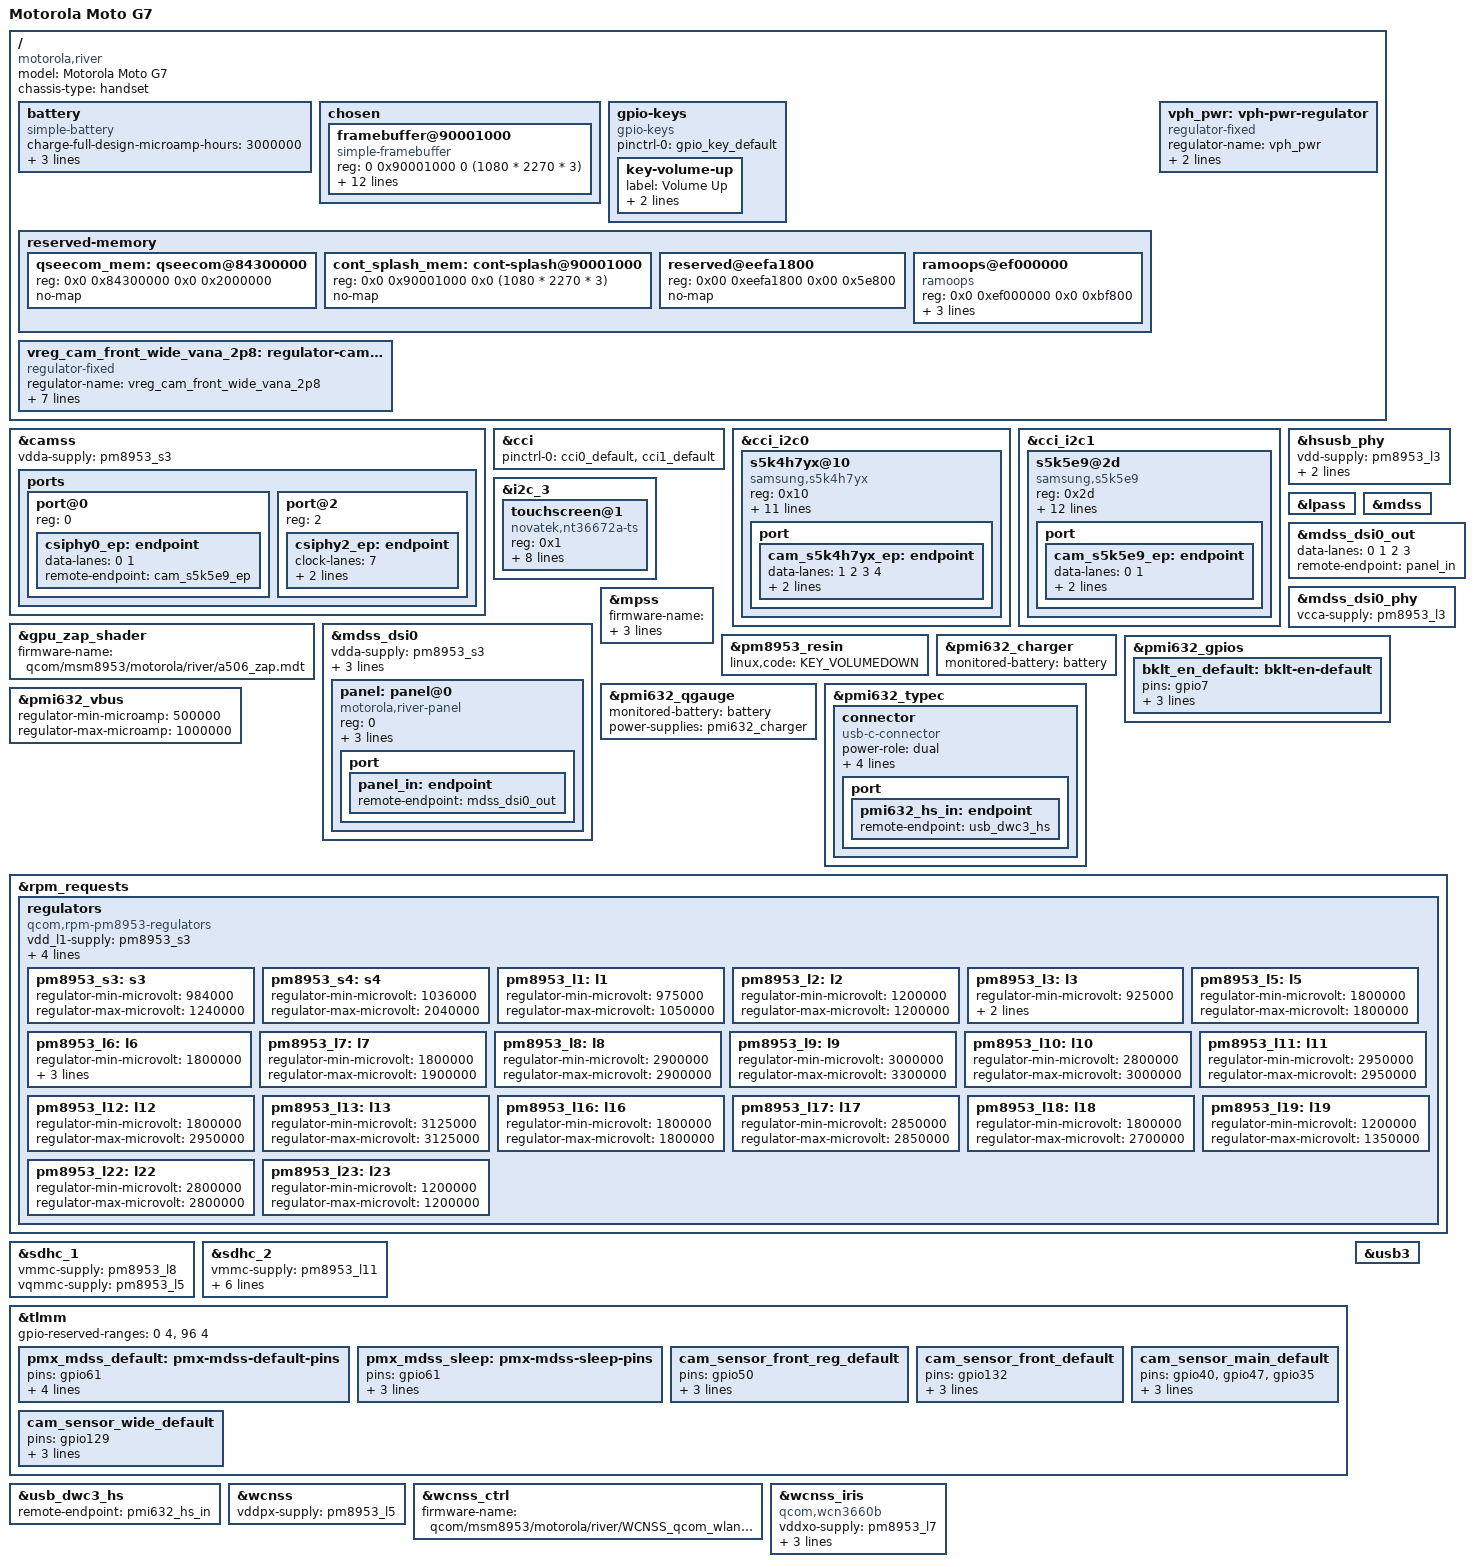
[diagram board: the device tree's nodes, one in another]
// SPDX-License-Identifier: BSD-3-Clause
/*
 * Copyright (c) 2022, Gabriela David
 * Copyright (c) 2026, Val Packett <val@packett.cool>
 */
/dts-v1/;

#include "sdm632.dtsi"
#include "pm8953.dtsi"
#include "pmi632.dtsi"

/delete-node/ &cont_splash_mem;
/delete-node/ &qseecom_mem;

/ {
	model = "Motorola Moto G7";
	compatible = "motorola,river", "qcom,sdm632";
	chassis-type = "handset";

	battery: battery {
		compatible = "simple-battery";

		charge-full-design-microamp-hours = <3000000>;
		/* XXX: Conservative value, downstream qcom,fastchg-current-ma is 3A */
		constant-charge-current-max-microamp = <1500000>;
		voltage-min-design-microvolt = <3400000>;
		voltage-max-design-microvolt = <4400000>;
	};

	chosen {
		#address-cells = <2>;
		#size-cells = <2>;
		ranges;

		framebuffer@90001000 {
			compatible = "simple-framebuffer";
			reg = <0 0x90001000 0 (1080 * 2270 * 3)>;

			width = <1080>;
			height = <2270>;
			stride = <(1080 * 3)>;
			format = "r8g8b8";

			power-domains = <&gcc MDSS_GDSC>;

			clocks = <&gcc GCC_MDSS_AHB_CLK>,
				 <&gcc GCC_MDSS_AXI_CLK>,
				 <&gcc GCC_MDSS_VSYNC_CLK>,
				 <&gcc GCC_MDSS_MDP_CLK>,
				 <&gcc GCC_MDSS_BYTE0_CLK>,
				 <&gcc GCC_MDSS_PCLK0_CLK>,
				 <&gcc GCC_MDSS_ESC0_CLK>;
		};
	};

	gpio-keys {
		compatible = "gpio-keys";

		pinctrl-0 = <&gpio_key_default>;
		pinctrl-names = "default";

		key-volume-up {
			label = "Volume Up";
			gpios = <&tlmm 85 GPIO_ACTIVE_LOW>;
			linux,code = <KEY_VOLUMEUP>;
		};
	};

	reserved-memory {
		qseecom_mem: qseecom@84300000 {
			reg = <0x0 0x84300000 0x0 0x2000000>;
			no-map;
		};

		cont_splash_mem: cont-splash@90001000 {
			reg = <0x0 0x90001000 0x0 (1080 * 2270 * 3)>;
			no-map;
		};

		reserved@eefa1800 {
			reg = <0x00 0xeefa1800 0x00 0x5e800>;
			no-map;
		};

		ramoops@ef000000 {
			compatible = "ramoops";
			reg = <0x0 0xef000000 0x0 0xbf800>;
			console-size = <0x40000>;
			pmsg-size = <0x40000>;
			record-size = <0x3f800>;
		};
	};

	vreg_cam_front_wide_vana_2p8: regulator-cam-front-wide-vana {
		compatible = "regulator-fixed";
		regulator-name = "vreg_cam_front_wide_vana_2p8";

		regulator-min-microvolt = <2800000>;
		regulator-max-microvolt = <2800000>;

		gpio = <&tlmm 50 GPIO_ACTIVE_HIGH>;
		enable-active-high;

		pinctrl-names = "default";
		pinctrl-0 = <&cam_sensor_front_reg_default>;

		vin-supply = <&pm8953_l22>;

		regulator-always-on;
	};

	vph_pwr: vph-pwr-regulator {
		compatible = "regulator-fixed";
		regulator-name = "vph_pwr";
		regulator-always-on;
		regulator-boot-on;
	};
};

&camss {
	status = "okay";
	vdda-supply = <&pm8953_s3>;

	ports {
		port@0 {
			reg = <0>;

			csiphy0_ep: endpoint {
				data-lanes = <0 1>;
				remote-endpoint = <&cam_s5k5e9_ep>;
			};
		};

		port@2 {
			reg = <2>;

			csiphy2_ep: endpoint {
				clock-lanes = <7>;
				data-lanes = <0 1 2 3>;
				remote-endpoint = <&cam_s5k4h7yx_ep>;
			};
		};
	};
};

&cci {
	pinctrl-0 = <&cci0_default &cci1_default>;
	pinctrl-names = "default";

	status = "okay";
};

&cci_i2c0 {
	s5k4h7yx@10 { /* Front camera */
		compatible = "samsung,s5k4h7yx";
		reg = <0x10>;

		vdda-supply = <&vreg_cam_front_wide_vana_2p8>;
		vddd-supply = <&pm8953_l23>;
		vddio-supply = <&pm8953_l6>;

		clocks = <&gcc GCC_CAMSS_MCLK1_CLK>;
		assigned-clocks = <&gcc GCC_CAMSS_MCLK1_CLK>;
		assigned-clock-rates = <24000000>;

		reset-gpios = <&tlmm 132 GPIO_ACTIVE_LOW>; /* "standby" downstream */
		pinctrl-0 = <&camss_mclk1_default &cam_sensor_front_default>;
		pinctrl-names = "default";

		orientation = <0>;
		rotation = <90>;

		port {
			cam_s5k4h7yx_ep: endpoint {
				data-lanes = <1 2 3 4>;
				link-frequencies = /bits/ 64 <600000000>; // FIXME
				remote-endpoint = <&csiphy2_ep>;
			};
		};
	};
};

&cci_i2c1 {
	s5k5e9@2d { /* Wide camera */
		compatible = "samsung,s5k5e9";
		reg = <0x2d>;

		vana-supply = <&vreg_cam_front_wide_vana_2p8>;
		vdig-supply = <&pm8953_l23>;
		vio-supply = <&pm8953_l6>;

		clocks = <&gcc GCC_CAMSS_MCLK2_CLK>;
		clock-names = "xvclk";
		clock-frequency = <19200000>;
		assigned-clocks = <&gcc GCC_CAMSS_MCLK2_CLK>;
		assigned-clock-rates = <19200000>;

		reset-gpios = <&tlmm 129 GPIO_ACTIVE_HIGH>;
		pinctrl-0 = <&camss_mclk2_default &cam_sensor_wide_default>;
		pinctrl-names = "default";

		orientation = <1>;
		rotation = <270>;

		port {
			cam_s5k5e9_ep: endpoint {
				data-lanes = <0 1>;
				link-frequencies = /bits/ 64 <480000000>;
				remote-endpoint = <&csiphy0_ep>;
			};
		};
	};
};

&gpu_zap_shader {
	firmware-name = "qcom/msm8953/motorola/river/a506_zap.mdt";
};

&hsusb_phy {
	vdd-supply = <&pm8953_l3>;
	vdda-pll-supply = <&pm8953_l7>;
	vdda-phy-dpdm-supply = <&pm8953_l13>;

	status = "okay";
};

&i2c_3 {
	status = "okay";

	touchscreen@1 {
		compatible = "novatek,nt36672a-ts";
		reg = <0x1>;

		interrupts-extended = <&tlmm 65 IRQ_TYPE_EDGE_FALLING>;
		reset-gpios = <&tlmm 64 GPIO_ACTIVE_HIGH>;
		panel = <&panel>;

		iovcc-supply = <&pm8953_l6>;
		vcc-supply = <&pm8953_l10>;

		touchscreen-size-x = <1080>;
		touchscreen-size-y = <2270>;
	};
};

&lpass {
	status = "okay";
};

&mdss {
	status = "okay";
};

&mdss_dsi0 {
	vdda-supply = <&pm8953_s3>;
	vddio-supply = <&pm8953_l6>;

	pinctrl-0 = <&pmx_mdss_default &mdss_te_default>;
	pinctrl-1 = <&pmx_mdss_sleep &mdss_te_default>;
	pinctrl-names = "default", "sleep";

	status = "okay";

	panel: panel@0 {
		compatible = "motorola,river-panel";
		reg = <0>;

		reset-gpios = <&tlmm 61 GPIO_ACTIVE_LOW>;

		iovcc-supply = <&pm8953_l6>;

		pinctrl-0 = <&bklt_en_default>;
		pinctrl-names = "default";

		port {
			panel_in: endpoint {
				remote-endpoint = <&mdss_dsi0_out>;
			};
		};
	};
};

&mdss_dsi0_out {
	data-lanes = <0 1 2 3>;
	remote-endpoint = <&panel_in>;
};

&mdss_dsi0_phy {
	vcca-supply = <&pm8953_l3>;

	status = "okay";
};

&mpss {
	firmware-name = "qcom/msm8953/motorola/river/mba.mbn",
			"qcom/msm8953/motorola/river/modem.mbn";
	pll-supply = <&pm8953_l7>;

	status = "okay";
};

&pm8953_resin {
	linux,code = <KEY_VOLUMEDOWN>;
	status = "okay";
};

&pmi632_charger {
	monitored-battery = <&battery>;

	status = "okay";
};

&pmi632_gpios {
	bklt_en_default: bklt-en-default {
		pins = "gpio7";
		function = "normal";
		power-source = <0x00>;
		output-high;
	};
};

&pmi632_qgauge {
	monitored-battery = <&battery>;
	power-supplies = <&pmi632_charger>;

	status = "okay";
};

&pmi632_typec {
	status = "okay";

	connector {
		compatible = "usb-c-connector";

		power-role = "dual";
		data-role = "dual";
		self-powered;

		typec-power-opmode = "default";
		pd-disable;

		port {
			pmi632_hs_in: endpoint {
				remote-endpoint = <&usb_dwc3_hs>;
			};
		};
	};
};

&pmi632_vbus {
	regulator-min-microamp = <500000>;
	regulator-max-microamp = <1000000>;
	status = "okay";
};

&rpm_requests {
	regulators {
		compatible = "qcom,rpm-pm8953-regulators";

		vdd_l1-supply = <&pm8953_s3>;
		vdd_l2_l3-supply = <&pm8953_s3>;
		vdd_l4_l5_l6_l7_l16_l19-supply = <&pm8953_s4>;
		vdd_l8_l11_l12_l13_l14_l15-supply = <&vph_pwr>;
		vdd_l9_l10_l17_l18_l22-supply = <&vph_pwr>;

		pm8953_s3: s3 {
			regulator-min-microvolt = <984000>;
			regulator-max-microvolt = <1240000>;
		};

		pm8953_s4: s4 {
			regulator-min-microvolt = <1036000>;
			regulator-max-microvolt = <2040000>;
		};

		pm8953_l1: l1 {
			regulator-min-microvolt = <975000>;
			regulator-max-microvolt = <1050000>;
		};

		pm8953_l2: l2 {
			regulator-min-microvolt = <1200000>;
			regulator-max-microvolt = <1200000>;
		};

		pm8953_l3: l3 {
			regulator-min-microvolt = <925000>;
			regulator-max-microvolt = <925000>;
			regulator-allow-set-load;
		};

		pm8953_l5: l5 {
			regulator-min-microvolt = <1800000>;
			regulator-max-microvolt = <1800000>;
		};

		pm8953_l6: l6 {
			regulator-min-microvolt = <1800000>;
			regulator-max-microvolt = <1800000>;
			regulator-always-on;
			regulator-boot-on;
		};

		pm8953_l7: l7 {
			regulator-min-microvolt = <1800000>;
			regulator-max-microvolt = <1900000>;
		};

		pm8953_l8: l8 {
			regulator-min-microvolt = <2900000>;
			regulator-max-microvolt = <2900000>;
		};

		pm8953_l9: l9 {
			regulator-min-microvolt = <3000000>;
			regulator-max-microvolt = <3300000>;
		};

		pm8953_l10: l10 {
			regulator-min-microvolt = <2800000>;
			regulator-max-microvolt = <3000000>;
		};

		pm8953_l11: l11 {
			regulator-min-microvolt = <2950000>;
			regulator-max-microvolt = <2950000>;
		};

		pm8953_l12: l12 {
			regulator-min-microvolt = <1800000>;
			regulator-max-microvolt = <2950000>;
		};

		pm8953_l13: l13 {
			regulator-min-microvolt = <3125000>;
			regulator-max-microvolt = <3125000>;
		};

		pm8953_l16: l16 {
			regulator-min-microvolt = <1800000>;
			regulator-max-microvolt = <1800000>;
		};

		pm8953_l17: l17 {
			regulator-min-microvolt = <2850000>;
			regulator-max-microvolt = <2850000>;
		};

		pm8953_l18: l18 {
			regulator-min-microvolt = <1800000>;
			regulator-max-microvolt = <2700000>;
		};

		pm8953_l19: l19 {
			regulator-min-microvolt = <1200000>;
			regulator-max-microvolt = <1350000>;
		};

		pm8953_l22: l22 {
			regulator-min-microvolt = <2800000>;
			regulator-max-microvolt = <2800000>;
		};

		pm8953_l23: l23 {
			regulator-min-microvolt = <1200000>;
			regulator-max-microvolt = <1200000>;
		};
	};
};

&sdhc_1 {
	vmmc-supply = <&pm8953_l8>;
	vqmmc-supply = <&pm8953_l5>;

	status = "okay";
};

&sdhc_2 {
	vmmc-supply = <&pm8953_l11>;
	vqmmc-supply = <&pm8953_l12>;

	cd-gpios = <&tlmm 133 GPIO_ACTIVE_HIGH>;

	pinctrl-0 = <&sdc2_clk_on &sdc2_cmd_on &sdc2_data_on &sdc2_cd_on>;
	pinctrl-1 = <&sdc2_clk_off &sdc2_cmd_off &sdc2_data_off &sdc2_cd_off>;
	pinctrl-names = "default", "sleep";

	status = "okay";
};

&tlmm {
	/*
	 * 0-3: touch panel firmware (SPI)
	 * 96-99: fingerprint reader (SPI)
	 */
	gpio-reserved-ranges = <0 4>, <96 4>;

	pmx_mdss_default: pmx-mdss-default-pins {
		pins = "gpio61";
		function = "gpio";
		drive-strength = <8>;
		bias-disable;
		output-high;
	};

	pmx_mdss_sleep: pmx-mdss-sleep-pins {
		pins = "gpio61";
		function = "gpio";
		drive-strength = <2>;
		bias-pull-down;
	};

	cam_sensor_front_reg_default: cam_sensor_front_reg_default {
		pins = "gpio50";
		function = "gpio";
		drive-strength = <2>;
		bias-disable;
	};

	cam_sensor_front_default: cam_sensor_front_default {
		pins = "gpio132";
		function = "gpio";
		drive-strength = <2>;
		bias-disable;
	};

	cam_sensor_main_default: cam_sensor_main_default {
		pins = "gpio40", "gpio47", "gpio35";
		function = "gpio";
		drive-strength = <2>;
		bias-disable;
	};

	cam_sensor_wide_default: cam_sensor_wide_default {
		pins = "gpio129";
		function = "gpio";
		drive-strength = <2>;
		bias-disable;
	};
};

&usb3 {
	status = "okay";
};

&usb_dwc3_hs {
	remote-endpoint = <&pmi632_hs_in>;
};

&wcnss {
	vddpx-supply = <&pm8953_l5>;

	status = "okay";
};

&wcnss_ctrl {
	firmware-name = "qcom/msm8953/motorola/river/WCNSS_qcom_wlan_nv.bin";
};

&wcnss_iris {
	compatible = "qcom,wcn3660b";

	vddxo-supply = <&pm8953_l7>;
	vddrfa-supply = <&pm8953_l19>;
	vddpa-supply = <&pm8953_l9>;
	vdddig-supply = <&pm8953_l5>;
};
